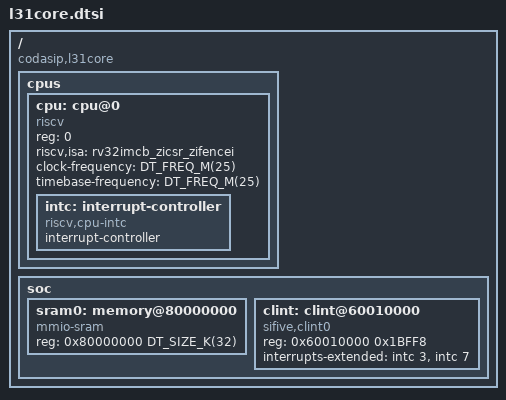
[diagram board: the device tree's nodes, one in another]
/*
 * Copyright (c) 2025 LTH
 *
 * SPDX-License-Identifier: Apache-2.0
 */

#include <skeleton.dtsi>
#include <freq.h>
#include <mem.h>

/ {
    compatible = "codasip,l31core";

    cpus {
        #address-cells = <1>;
        #size-cells = <0>;

        cpu: cpu@0 {
            compatible = "riscv";
            device_type = "cpu";
            reg = <0>;
            riscv,isa = "rv32imcb_zicsr_zifencei";
            clock-frequency = <DT_FREQ_M(25)>;
            timebase-frequency = <DT_FREQ_M(25)>;
            status = "okay";
            intc: interrupt-controller {
                compatible = "riscv,cpu-intc";
                #address-cells = <0>;
                #interrupt-cells = <1>;
                interrupt-controller;
            };
        };
    };

    soc {
        #address-cells = <1>;
        #size-cells = <1>;

        sram0: memory@80000000 {
            compatible = "mmio-sram";
            reg = <0x80000000 DT_SIZE_K(32)>;    // 32 KB
        };

        clint: clint@60010000 {
            compatible = "sifive,clint0";
            reg = <0x60010000 0x1BFF8>;
            interrupts-extended = <&intc 3>, <&intc 7>;
        };
    };
};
